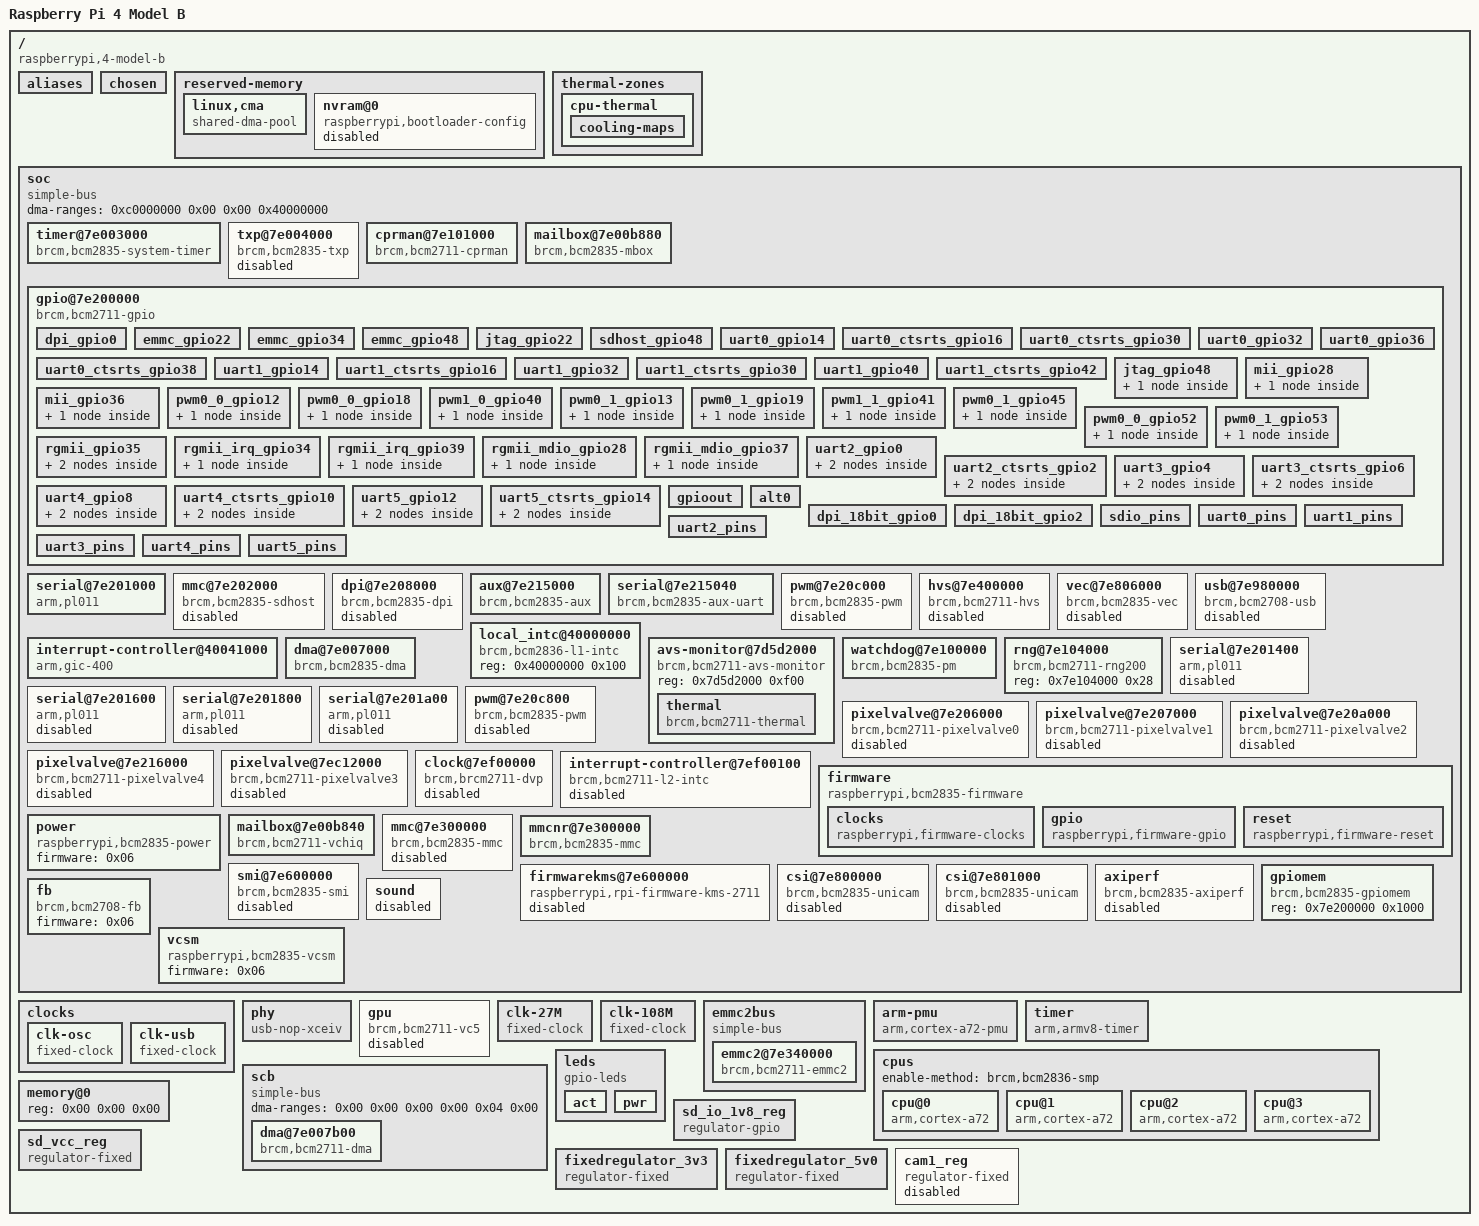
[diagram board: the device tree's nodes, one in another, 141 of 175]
/dts-v1/;

/memreserve/	0x0000000000000000 0x0000000000001000;
/ {
	compatible = "raspberrypi,4-model-b\0brcm,bcm2711";
	model = "Raspberry Pi 4 Model B";
	#address-cells = <0x02>;
	#size-cells = <0x01>;
	interrupt-parent = <0x01>;

	aliases {
		serial0 = "/soc/serial@7e215040";
		serial1 = "/soc/serial@7e201000";
		emmc2bus = "/emmc2bus";
		pcie0 = "/scb/pcie@7d500000";
		blconfig = "/reserved-memory/nvram@0";
		aux = "/soc/aux@7e215000";
		sound = "/soc/sound";
		soc = "/soc";
		dma = "/soc/dma@7e007000";
		watchdog = "/soc/watchdog@7e100000";
		random = "/soc/rng@7e104000";
		mailbox = "/soc/mailbox@7e00b880";
		gpio = "/soc/gpio@7e200000";
		uart0 = "/soc/serial@7e201000";
		uart1 = "/soc/serial@7e215040";
		sdhost = "/soc/mmc@7e202000";
		mmc = "/soc/mmc@7e300000";
		mmc1 = "/soc/mmcnr@7e300000";
		mmc0 = "/emmc2bus/emmc2@7e340000";
		usb = "/soc/usb@7e980000";
		leds = "/leds";
		fb = "/soc/fb";
		thermal = "/soc/avs-monitor@7d5d2000/thermal";
		axiperf = "/soc/axiperf";
		mmc2 = "/soc/mmc@7e202000";
	};

	chosen {
		bootargs = "coherent_pool=1M 8250.nr_uarts=1 snd_bcm2835.enable_compat_alsa=0 snd_bcm2835.enable_hdmi=1";
	};

	reserved-memory {
		#address-cells = <0x02>;
		#size-cells = <0x01>;
		ranges;
		phandle = <0x41>;

		linux,cma {
			compatible = "shared-dma-pool";
			size = <0x4000000>;
			reusable;
			linux,cma-default;
			alloc-ranges = <0x00 0x00 0x30000000>;
			phandle = <0x42>;
		};

		nvram@0 {
			compatible = "raspberrypi,bootloader-config\0nvmem-rmem";
			#address-cells = <0x01>;
			#size-cells = <0x01>;
			reg = <0x00 0x00 0x00>;
			no-map;
			status = "disabled";
			phandle = <0x43>;
		};
	};

	thermal-zones {

		cpu-thermal {
			polling-delay-passive = <0x00>;
			polling-delay = <0x3e8>;
			coefficients = <0xfffffe19 0x641b8>;
			thermal-sensors = <0x02>;
			phandle = <0x44>;

			cooling-maps {
			};
		};
	};

	soc {
		compatible = "simple-bus";
		#address-cells = <0x01>;
		#size-cells = <0x01>;
		ranges = <0x7e000000 0x00 0xfe000000 0x1800000 0x7c000000 0x00 0xfc000000 0x2000000 0x40000000 0x00 0xff800000 0x800000>;
		dma-ranges = <0xc0000000 0x00 0x00 0x40000000>;
		phandle = <0x45>;

		timer@7e003000 {
			compatible = "brcm,bcm2835-system-timer";
			reg = <0x7e003000 0x1000>;
			interrupts = <0x00 0x40 0x04 0x00 0x41 0x04 0x00 0x42 0x04 0x00 0x43 0x04>;
			clock-frequency = <0xf4240>;
			phandle = <0x46>;
		};

		txp@7e004000 {
			compatible = "brcm,bcm2835-txp";
			reg = <0x7e004000 0x20>;
			interrupts = <0x00 0x4b 0x04>;
			status = "disabled";
			phandle = <0x47>;
		};

		cprman@7e101000 {
			compatible = "brcm,bcm2711-cprman";
			#clock-cells = <0x01>;
			reg = <0x7e101000 0x2000>;
			clocks = <0x03 0x04 0x00 0x04 0x01 0x04 0x02 0x05 0x00 0x05 0x01 0x05 0x02>;
			firmware = <0x06>;
			phandle = <0x07>;
		};

		mailbox@7e00b880 {
			compatible = "brcm,bcm2835-mbox";
			reg = <0x7e00b880 0x40>;
			interrupts = <0x00 0x21 0x04>;
			#mbox-cells = <0x00>;
			phandle = <0x22>;
		};

		gpio@7e200000 {
			compatible = "brcm,bcm2711-gpio";
			reg = <0x7e200000 0xb4>;
			interrupts = <0x00 0x71 0x04 0x00 0x72 0x04>;
			gpio-controller;
			#gpio-cells = <0x02>;
			interrupt-controller;
			#interrupt-cells = <0x02>;
			pinctrl-names = "default";
			gpio-line-names = "ID_SDA\0ID_SCL\0SDA1\0SCL1\0GPIO_GCLK\0GPIO5\0GPIO6\0SPI_CE1_N\0SPI_CE0_N\0SPI_MISO\0SPI_MOSI\0SPI_SCLK\0GPIO12\0GPIO13\0TXD1\0RXD1\0GPIO16\0GPIO17\0GPIO18\0GPIO19\0GPIO20\0GPIO21\0GPIO22\0GPIO23\0GPIO24\0GPIO25\0GPIO26\0GPIO27\0RGMII_MDIO\0RGMIO_MDC\0CTS0\0RTS0\0TXD0\0RXD0\0SD1_CLK\0SD1_CMD\0SD1_DATA0\0SD1_DATA1\0SD1_DATA2\0SD1_DATA3\0PWM0_MISO\0PWM1_MOSI\0STATUS_LED_G_CLK\0SPIFLASH_CE_N\0SDA0\0SCL0\0RGMII_RXCLK\0RGMII_RXCTL\0RGMII_RXD0\0RGMII_RXD1\0RGMII_RXD2\0RGMII_RXD3\0RGMII_TXCLK\0RGMII_TXCTL\0RGMII_TXD0\0RGMII_TXD1\0RGMII_TXD2\0RGMII_TXD3";
			phandle = <0x0f>;

			dpi_gpio0 {
				brcm,pins = <0x00 0x01 0x02 0x03 0x04 0x05 0x06 0x07 0x08 0x09 0x0a 0x0b 0x0c 0x0d 0x0e 0x0f 0x10 0x11 0x12 0x13 0x14 0x15 0x16 0x17 0x18 0x19 0x1a 0x1b>;
				brcm,function = <0x06>;
				phandle = <0x48>;
			};

			emmc_gpio22 {
				brcm,pins = <0x16 0x17 0x18 0x19 0x1a 0x1b>;
				brcm,function = <0x07>;
				phandle = <0x49>;
			};

			emmc_gpio34 {
				brcm,pins = <0x22 0x23 0x24 0x25 0x26 0x27>;
				brcm,function = <0x07>;
				brcm,pull = <0x00 0x02 0x02 0x02 0x02 0x02>;
				phandle = <0x4a>;
			};

			emmc_gpio48 {
				brcm,pins = <0x30 0x31 0x32 0x33 0x34 0x35>;
				brcm,function = <0x07>;
				phandle = <0x24>;
			};

			jtag_gpio22 {
				brcm,pins = <0x16 0x17 0x18 0x19 0x1a 0x1b>;
				brcm,function = <0x03>;
				phandle = <0x54>;
			};

			sdhost_gpio48 {
				brcm,pins = <0x30 0x31 0x32 0x33 0x34 0x35>;
				brcm,function = <0x04>;
				phandle = <0x57>;
			};

			uart0_gpio14 {
				brcm,pins = <0x0e 0x0f>;
				brcm,function = <0x04>;
				phandle = <0x5c>;
			};

			uart0_ctsrts_gpio16 {
				brcm,pins = <0x10 0x11>;
				brcm,function = <0x07>;
				phandle = <0x5d>;
			};

			uart0_ctsrts_gpio30 {
				brcm,pins = <0x1e 0x1f>;
				brcm,function = <0x07>;
				brcm,pull = <0x02 0x00>;
				phandle = <0x5e>;
			};

			uart0_gpio32 {
				brcm,pins = <0x20 0x21>;
				brcm,function = <0x07>;
				brcm,pull = <0x00 0x02>;
				phandle = <0x5f>;
			};

			uart0_gpio36 {
				brcm,pins = <0x24 0x25>;
				brcm,function = <0x06>;
				phandle = <0x60>;
			};

			uart0_ctsrts_gpio38 {
				brcm,pins = <0x26 0x27>;
				brcm,function = <0x06>;
				phandle = <0x61>;
			};

			uart1_gpio14 {
				brcm,pins = <0x0e 0x0f>;
				brcm,function = <0x02>;
				phandle = <0x62>;
			};

			uart1_ctsrts_gpio16 {
				brcm,pins = <0x10 0x11>;
				brcm,function = <0x02>;
				phandle = <0x63>;
			};

			uart1_gpio32 {
				brcm,pins = <0x20 0x21>;
				brcm,function = <0x02>;
				phandle = <0x64>;
			};

			uart1_ctsrts_gpio30 {
				brcm,pins = <0x1e 0x1f>;
				brcm,function = <0x02>;
				phandle = <0x65>;
			};

			uart1_gpio40 {
				brcm,pins = <0x28 0x29>;
				brcm,function = <0x02>;
				phandle = <0x66>;
			};

			uart1_ctsrts_gpio42 {
				brcm,pins = <0x2a 0x2b>;
				brcm,function = <0x02>;
				phandle = <0x67>;
			};

			jtag_gpio48 {
				phandle = <0x76>;

				pins-jtag {
					pins = "gpio48\0gpio49\0gpio50\0gpio51\0gpio52\0gpio53";
					function = "alt4";
				};
			};

			mii_gpio28 {
				phandle = <0x77>;

				pins-mii {
					pins = "gpio28\0gpio29\0gpio30\0gpio31";
					function = "alt4";
				};
			};

			mii_gpio36 {
				phandle = <0x78>;

				pins-mii {
					pins = "gpio36\0gpio37\0gpio38\0gpio39";
					function = "alt5";
				};
			};

			pwm0_0_gpio12 {
				phandle = <0x7a>;

				pin-pwm {
					pins = "gpio12";
					function = "alt0";
					bias-disable;
				};
			};

			pwm0_0_gpio18 {
				phandle = <0x7b>;

				pin-pwm {
					pins = "gpio18";
					function = "alt5";
					bias-disable;
				};
			};

			pwm1_0_gpio40 {
				phandle = <0x1a>;

				pin-pwm {
					pins = "gpio40";
					function = "alt0";
					bias-disable;
				};
			};

			pwm0_1_gpio13 {
				phandle = <0x7c>;

				pin-pwm {
					pins = "gpio13";
					function = "alt0";
					bias-disable;
				};
			};

			pwm0_1_gpio19 {
				phandle = <0x7d>;

				pin-pwm {
					pins = "gpio19";
					function = "alt5";
					bias-disable;
				};
			};

			pwm1_1_gpio41 {
				phandle = <0x1b>;

				pin-pwm {
					pins = "gpio41";
					function = "alt0";
					bias-disable;
				};
			};

			pwm0_1_gpio45 {
				phandle = <0x7e>;

				pin-pwm {
					pins = "gpio45";
					function = "alt0";
					bias-disable;
				};
			};

			pwm0_0_gpio52 {
				phandle = <0x7f>;

				pin-pwm {
					pins = "gpio52";
					function = "alt1";
					bias-disable;
				};
			};

			pwm0_1_gpio53 {
				phandle = <0x80>;

				pin-pwm {
					pins = "gpio53";
					function = "alt1";
					bias-disable;
				};
			};

			rgmii_gpio35 {
				phandle = <0x81>;

				pin-start-stop {
					pins = "gpio35";
					function = "alt4";
				};

				pin-rx-ok {
					pins = "gpio36";
					function = "alt4";
				};
			};

			rgmii_irq_gpio34 {
				phandle = <0x82>;

				pin-irq {
					pins = "gpio34";
					function = "alt5";
				};
			};

			rgmii_irq_gpio39 {
				phandle = <0x83>;

				pin-irq {
					pins = "gpio39";
					function = "alt4";
				};
			};

			rgmii_mdio_gpio28 {
				phandle = <0x84>;

				pins-mdio {
					pins = "gpio28\0gpio29";
					function = "alt5";
				};
			};

			rgmii_mdio_gpio37 {
				phandle = <0x85>;

				pins-mdio {
					pins = "gpio37\0gpio38";
					function = "alt4";
				};
			};

			uart2_gpio0 {
				phandle = <0x8c>;

				pin-tx {
					pins = "gpio0";
					function = "alt4";
					bias-disable;
				};

				pin-rx {
					pins = "gpio1";
					function = "alt4";
					bias-pull-up;
				};
			};

			uart2_ctsrts_gpio2 {
				phandle = <0x8d>;

				pin-cts {
					pins = "gpio2";
					function = "alt4";
					bias-pull-up;
				};

				pin-rts {
					pins = "gpio3";
					function = "alt4";
					bias-disable;
				};
			};

			uart3_gpio4 {
				phandle = <0x8e>;

				pin-tx {
					pins = "gpio4";
					function = "alt4";
					bias-disable;
				};

				pin-rx {
					pins = "gpio5";
					function = "alt4";
					bias-pull-up;
				};
			};

			uart3_ctsrts_gpio6 {
				phandle = <0x8f>;

				pin-cts {
					pins = "gpio6";
					function = "alt4";
					bias-pull-up;
				};

				pin-rts {
					pins = "gpio7";
					function = "alt4";
					bias-disable;
				};
			};

			uart4_gpio8 {
				phandle = <0x90>;

				pin-tx {
					pins = "gpio8";
					function = "alt4";
					bias-disable;
				};

				pin-rx {
					pins = "gpio9";
					function = "alt4";
					bias-pull-up;
				};
			};

			uart4_ctsrts_gpio10 {
				phandle = <0x91>;

				pin-cts {
					pins = "gpio10";
					function = "alt4";
					bias-pull-up;
				};

				pin-rts {
					pins = "gpio11";
					function = "alt4";
					bias-disable;
				};
			};

			uart5_gpio12 {
				phandle = <0x92>;

				pin-tx {
					pins = "gpio12";
					function = "alt4";
					bias-disable;
				};

				pin-rx {
					pins = "gpio13";
					function = "alt4";
					bias-pull-up;
				};
			};

			uart5_ctsrts_gpio14 {
				phandle = <0x93>;

				pin-cts {
					pins = "gpio14";
					function = "alt4";
					bias-pull-up;
				};

				pin-rts {
					pins = "gpio15";
					function = "alt4";
					bias-disable;
				};
			};

			gpioout {
				brcm,pins = <0x06>;
				brcm,function = <0x01>;
				phandle = <0x94>;
			};

			alt0 {
				brcm,pins = <0x04 0x05 0x07 0x08 0x09 0x0a 0x0b>;
				brcm,function = <0x04>;
				phandle = <0x95>;
			};

			dpi_18bit_gpio0 {
				brcm,pins = <0x00 0x01 0x02 0x03 0x04 0x05 0x06 0x07 0x08 0x09 0x0a 0x0b 0x0c 0x0d 0x0e 0x0f 0x10 0x11 0x12 0x13 0x14 0x15>;
				brcm,function = <0x06>;
				phandle = <0x96>;
			};

			dpi_18bit_gpio2 {
				brcm,pins = <0x02 0x03 0x04 0x05 0x06 0x07 0x08 0x09 0x0a 0x0b 0x0c 0x0d 0x0e 0x0f 0x10 0x11 0x12 0x13 0x14 0x15>;
				brcm,function = <0x06>;
				phandle = <0x97>;
			};

			sdio_pins {
				brcm,pins = <0x22 0x23 0x24 0x25 0x26 0x27>;
				brcm,function = <0x07>;
				brcm,pull = <0x00 0x02 0x02 0x02 0x02 0x02>;
				phandle = <0x25>;
			};

			uart0_pins {
				brcm,pins = <0x20 0x21>;
				brcm,function = <0x07>;
				brcm,pull = <0x00 0x02>;
				phandle = <0x08>;
			};

			uart1_pins {
				brcm,pins;
				brcm,function;
				brcm,pull;
				phandle = <0x15>;
			};

			uart2_pins {
				brcm,pins = <0x00 0x01>;
				brcm,function = <0x03>;
				brcm,pull = <0x00 0x02>;
				phandle = <0xa5>;
			};

			uart3_pins {
				brcm,pins = <0x04 0x05>;
				brcm,function = <0x03>;
				brcm,pull = <0x00 0x02>;
				phandle = <0xa6>;
			};

			uart4_pins {
				brcm,pins = <0x08 0x09>;
				brcm,function = <0x03>;
				brcm,pull = <0x00 0x02>;
				phandle = <0xa7>;
			};

			uart5_pins {
				brcm,pins = <0x0c 0x0d>;
				brcm,function = <0x03>;
				brcm,pull = <0x00 0x02>;
				phandle = <0xa8>;
			};
		};

		serial@7e201000 {
			compatible = "arm,pl011\0arm,primecell";
			reg = <0x7e201000 0x200>;
			interrupts = <0x00 0x79 0x04>;
			clocks = <0x07 0x13 0x07 0x14>;
			clock-names = "uartclk\0apb_pclk";
			arm,primecell-periphid = <0x241011>;
			pinctrl-names = "default";
			pinctrl-0 = <0x08 0x09>;
			uart-has-rtscts;
			status = "okay";
			cts-event-workaround;
			skip-init;
			phandle = <0x30>;
		};

		mmc@7e202000 {
			compatible = "brcm,bcm2835-sdhost";
			reg = <0x7e202000 0x100>;
			interrupts = <0x00 0x78 0x04>;
			clocks = <0x07 0x14>;
			status = "disabled";
			dmas = <0x0b 0x2000000d>;
			dma-names = "rx-tx";
			bus-width = <0x04>;
			brcm,overclock-50 = <0x00>;
			brcm,pio-limit = <0x01>;
			phandle = <0x39>;
		};

		dpi@7e208000 {
			compatible = "brcm,bcm2835-dpi";
			reg = <0x7e208000 0x8c>;
			clocks = <0x07 0x14 0x07 0x2c>;
			clock-names = "core\0pixel";
			#address-cells = <0x01>;
			#size-cells = <0x00>;
			status = "disabled";
			phandle = <0xad>;
		};

		aux@7e215000 {
			compatible = "brcm,bcm2835-aux";
			#clock-cells = <0x01>;
			reg = <0x7e215000 0x08>;
			clocks = <0x07 0x14>;
			phandle = <0x14>;
		};

		serial@7e215040 {
			compatible = "brcm,bcm2835-aux-uart";
			reg = <0x7e215040 0x40>;
			interrupts = <0x00 0x5d 0x04>;
			clocks = <0x14 0x00>;
			status = "okay";
			pinctrl-names = "default";
			pinctrl-0 = <0x15>;
			skip-init;
			phandle = <0x31>;
		};

		pwm@7e20c000 {
			compatible = "brcm,bcm2835-pwm";
			reg = <0x7e20c000 0x28>;
			clocks = <0x07 0x1e>;
			assigned-clocks = <0x07 0x1e>;
			assigned-clock-rates = <0x989680>;
			#pwm-cells = <0x02>;
			status = "disabled";
			phandle = <0xb1>;
		};

		hvs@7e400000 {
			compatible = "brcm,bcm2711-hvs";
			reg = <0x7e400000 0x6000>;
			interrupts = <0x00 0x61 0x04>;
			clocks = <0x16 0x04>;
			status = "disabled";
			phandle = <0xb2>;
		};

		vec@7e806000 {
			compatible = "brcm,bcm2835-vec";
			reg = <0x7e806000 0x1000>;
			clocks = <0x07 0x18>;
			interrupts = <0x00 0x7b 0x04>;
			status = "disabled";
			power-domains = <0x13 0x07>;
			phandle = <0xb3>;
		};

		usb@7e980000 {
			compatible = "brcm,bcm2708-usb";
			reg = <0x7e980000 0x10000 0x7e00b200 0x200>;
			interrupts = <0x00 0x49 0x04 0x00 0x28 0x04>;
			#address-cells = <0x01>;
			#size-cells = <0x00>;
			clocks = <0x18>;
			clock-names = "otg";
			phys = <0x19>;
			phy-names = "usb2-phy";
			power-domains = <0x13 0x06>;
			interrupt-names = "usb\0soft";
			status = "disabled";
			phandle = <0xb4>;
		};

		local_intc@40000000 {
			compatible = "brcm,bcm2836-l1-intc";
			reg = <0x40000000 0x100>;
			phandle = <0xb5>;
		};

		interrupt-controller@40041000 {
			interrupt-controller;
			#interrupt-cells = <0x03>;
			compatible = "arm,gic-400";
			reg = <0x40041000 0x1000 0x40042000 0x2000 0x40044000 0x2000 0x40046000 0x2000>;
			interrupts = <0x01 0x09 0xf04>;
			phandle = <0x01>;
		};

		avs-monitor@7d5d2000 {
			compatible = "brcm,bcm2711-avs-monitor\0syscon\0simple-mfd";
			reg = <0x7d5d2000 0xf00>;
			phandle = <0xb6>;

			thermal {
				compatible = "brcm,bcm2711-thermal";
				#thermal-sensor-cells = <0x00>;
				phandle = <0x02>;
			};
		};

		dma@7e007000 {
			compatible = "brcm,bcm2835-dma";
			reg = <0x7e007000 0xb00>;
			interrupts = <0x00 0x50 0x04 0x00 0x51 0x04 0x00 0x52 0x04 0x00 0x53 0x04 0x00 0x54 0x04 0x00 0x55 0x04 0x00 0x56 0x04 0x00 0x57 0x04 0x00 0x57 0x04 0x00 0x58 0x04 0x00 0x58 0x04>;
			interrupt-names = "dma0\0dma1\0dma2\0dma3\0dma4\0dma5\0dma6\0dma7\0dma8\0dma9\0dma10";
			#dma-cells = <0x01>;
			brcm,dma-channel-mask = <0x7f5>;
			phandle = <0x0b>;
		};

		watchdog@7e100000 {
			compatible = "brcm,bcm2835-pm\0brcm,bcm2835-pm-wdt";
			#power-domain-cells = <0x01>;
			#reset-cells = <0x01>;
			reg = <0x7e100000 0x114 0x7e00a000 0x24 0x7ec11000 0x20>;
			clocks = <0x07 0x15 0x07 0x1d 0x07 0x17 0x07 0x16>;
			clock-names = "v3d\0peri_image\0h264\0isp";
			system-power-controller;
			phandle = <0x37>;
		};

		rng@7e104000 {
			compatible = "brcm,bcm2711-rng200";
			reg = <0x7e104000 0x28>;
			status = "okay";
			phandle = <0x38>;
		};

		serial@7e201400 {
			compatible = "arm,pl011\0arm,primecell";
			reg = <0x7e201400 0x200>;
			interrupts = <0x00 0x79 0x04>;
			clocks = <0x07 0x13 0x07 0x14>;
			clock-names = "uartclk\0apb_pclk";
			arm,primecell-periphid = <0x241011>;
			status = "disabled";
			phandle = <0xb7>;
		};

		serial@7e201600 {
			compatible = "arm,pl011\0arm,primecell";
			reg = <0x7e201600 0x200>;
			interrupts = <0x00 0x79 0x04>;
			clocks = <0x07 0x13 0x07 0x14>;
			clock-names = "uartclk\0apb_pclk";
			arm,primecell-periphid = <0x241011>;
			status = "disabled";
			phandle = <0xb8>;
		};

		serial@7e201800 {
			compatible = "arm,pl011\0arm,primecell";
			reg = <0x7e201800 0x200>;
			interrupts = <0x00 0x79 0x04>;
			clocks = <0x07 0x13 0x07 0x14>;
			clock-names = "uartclk\0apb_pclk";
			arm,primecell-periphid = <0x241011>;
			status = "disabled";
			phandle = <0xb9>;
		};

		serial@7e201a00 {
			compatible = "arm,pl011\0arm,primecell";
			reg = <0x7e201a00 0x200>;
			interrupts = <0x00 0x79 0x04>;
			clocks = <0x07 0x13 0x07 0x14>;
			clock-names = "uartclk\0apb_pclk";
			arm,primecell-periphid = <0x241011>;
			status = "disabled";
			phandle = <0xba>;
		};

		pixelvalve@7e206000 {
			compatible = "brcm,bcm2711-pixelvalve0";
			reg = <0x7e206000 0x100>;
			interrupts = <0x00 0x6d 0x04>;
			status = "disabled";
			phandle = <0xc3>;
		};

		pixelvalve@7e207000 {
			compatible = "brcm,bcm2711-pixelvalve1";
			reg = <0x7e207000 0x100>;
			interrupts = <0x00 0x6e 0x04>;
			status = "disabled";
			phandle = <0xc4>;
		};

		pixelvalve@7e20a000 {
			compatible = "brcm,bcm2711-pixelvalve2";
			reg = <0x7e20a000 0x100>;
			interrupts = <0x00 0x65 0x04>;
			status = "disabled";
			phandle = <0xc5>;
		};

		pwm@7e20c800 {
			compatible = "brcm,bcm2835-pwm";
			reg = <0x7e20c800 0x28>;
			clocks = <0x07 0x1e>;
			assigned-clocks = <0x07 0x1e>;
			assigned-clock-rates = <0x989680>;
			#pwm-cells = <0x02>;
			status = "disabled";
			pinctrl-names = "default";
			pinctrl-0 = <0x1a 0x1b>;
			phandle = <0xc6>;
		};

		pixelvalve@7e216000 {
			compatible = "brcm,bcm2711-pixelvalve4";
			reg = <0x7e216000 0x100>;
			interrupts = <0x00 0x6e 0x04>;
			status = "disabled";
			phandle = <0xc7>;
		};

		pixelvalve@7ec12000 {
			compatible = "brcm,bcm2711-pixelvalve3";
			reg = <0x7ec12000 0x100>;
			interrupts = <0x00 0x6a 0x04>;
			status = "disabled";
			phandle = <0xc8>;
		};

		clock@7ef00000 {
			compatible = "brcm,brcm2711-dvp";
			reg = <0x7ef00000 0x10>;
			clocks = <0x1c>;
			#clock-cells = <0x01>;
			#reset-cells = <0x01>;
			status = "disabled";
			phandle = <0x1d>;
		};

		interrupt-controller@7ef00100 {
			compatible = "brcm,bcm2711-l2-intc\0brcm,l2-intc";
			reg = <0x7ef00100 0x30>;
			interrupts = <0x00 0x60 0x04>;
			interrupt-controller;
			#interrupt-cells = <0x01>;
			status = "disabled";
			phandle = <0x1f>;
		};

		firmware {
			compatible = "raspberrypi,bcm2835-firmware\0simple-mfd";
			#address-cells = <0x01>;
			#size-cells = <0x01>;
			mboxes = <0x22>;
			dma-ranges;
			phandle = <0x06>;

			clocks {
				compatible = "raspberrypi,firmware-clocks";
				#clock-cells = <0x01>;
				phandle = <0x16>;
			};

			gpio {
				compatible = "raspberrypi,firmware-gpio";
				gpio-controller;
				#gpio-cells = <0x02>;
				gpio-line-names = "BT_ON\0WL_ON\0PWR_LED_OFF\0GLOBAL_RESET\0VDD_SD_IO_SEL\0CAM_GPIO\0SD_PWR_ON\0SD_OC_N";
				status = "okay";
				phandle = <0x0a>;
			};

			reset {
				compatible = "raspberrypi,firmware-reset";
				#reset-cells = <0x01>;
				phandle = <0x2d>;
			};
		};

		power {
			compatible = "raspberrypi,bcm2835-power";
			firmware = <0x06>;
			#power-domain-cells = <0x01>;
			phandle = <0x13>;
		};

		mailbox@7e00b840 {
			compatible = "brcm,bcm2711-vchiq";
			reg = <0x7e00b840 0x3c>;
			interrupts = <0x00 0x22 0x04>;
			phandle = <0xcb>;
		};

		mmc@7e300000 {
			compatible = "brcm,bcm2835-mmc\0brcm,bcm2835-sdhci";
			reg = <0x7e300000 0x100>;
			interrupts = <0x00 0x7e 0x04>;
			clocks = <0x07 0x1c>;
			dmas = <0x0b 0x0b>;
			dma-names = "rx-tx";
			brcm,overclock-50 = <0x00>;
			status = "disabled";
			pinctrl-names = "default";
			pinctrl-0 = <0x24>;
			bus-width = <0x04>;
			phandle = <0x3a>;
		};

		mmcnr@7e300000 {
			compatible = "brcm,bcm2835-mmc\0brcm,bcm2835-sdhci";
			reg = <0x7e300000 0x100>;
			interrupts = <0x00 0x7e 0x04>;
			clocks = <0x07 0x1c>;
			dmas = <0x0b 0x0b>;
			dma-names = "rx-tx";
			brcm,overclock-50 = <0x00>;
			non-removable;
			status = "okay";
			pinctrl-names = "default";
			pinctrl-0 = <0x25>;
			bus-width = <0x04>;
			phandle = <0x3b>;
		};

		firmwarekms@7e600000 {
			compatible = "raspberrypi,rpi-firmware-kms-2711";
			reg = <0x7e600000 0x100>;
			interrupts = <0x00 0x70 0x04>;
			brcm,firmware = <0x06>;
			status = "disabled";
			phandle = <0xcc>;
		};

		smi@7e600000 {
			compatible = "brcm,bcm2835-smi";
			reg = <0x7e600000 0x100>;
			interrupts = <0x00 0x70 0x04>;
			clocks = <0x07 0x2a>;
			assigned-clocks = <0x07 0x2a>;
			assigned-clock-rates = <0x7735940>;
			dmas = <0x0b 0x04>;
			dma-names = "rx-tx";
			status = "disabled";
			phandle = <0xcd>;
		};

		csi@7e800000 {
			compatible = "brcm,bcm2835-unicam";
			reg = <0x7e800000 0x800 0x7e802000 0x04>;
			interrupts = <0x00 0x66 0x04>;
			clocks = <0x07 0x2d 0x16 0x04>;
			clock-names = "lp\0vpu";
			power-domains = <0x13 0x0c>;
			#address-cells = <0x01>;
			#size-cells = <0x00>;
			#clock-cells = <0x01>;
			status = "disabled";
			phandle = <0xce>;
		};

		csi@7e801000 {
			compatible = "brcm,bcm2835-unicam";
			reg = <0x7e801000 0x800 0x7e802004 0x04>;
			interrupts = <0x00 0x67 0x04>;
			clocks = <0x07 0x2e 0x16 0x04>;
			clock-names = "lp\0vpu";
			power-domains = <0x13 0x0d>;
			#address-cells = <0x01>;
			#size-cells = <0x00>;
			#clock-cells = <0x01>;
			status = "disabled";
			brcm,num-data-lanes = <0x02>;
			phandle = <0xcf>;
		};

		axiperf {
			compatible = "brcm,bcm2835-axiperf";
			reg = <0x7e009800 0x100 0x7ee08000 0x100>;
			firmware = <0x06>;
			status = "disabled";
			phandle = <0x3c>;
		};

		gpiomem {
			compatible = "brcm,bcm2835-gpiomem";
			reg = <0x7e200000 0x1000>;
		};

		fb {
			compatible = "brcm,bcm2708-fb";
			firmware = <0x06>;
			status = "okay";
			phandle = <0xd0>;
		};

		vcsm {
			compatible = "raspberrypi,bcm2835-vcsm";
			firmware = <0x06>;
			status = "okay";
			phandle = <0xd1>;
		};

		sound {
			status = "disabled";
			phandle = <0xd2>;
		};
	};

	clocks {

		clk-osc {
			compatible = "fixed-clock";
			#clock-cells = <0x00>;
			clock-output-names = "osc";
			clock-frequency = <0x337f980>;
			phandle = <0x03>;
		};

		clk-usb {
			compatible = "fixed-clock";
			#clock-cells = <0x00>;
			clock-output-names = "otg";
			clock-frequency = <0x1c9c3800>;
			phandle = <0x18>;
		};
	};

	phy {
		compatible = "usb-nop-xceiv";
		#phy-cells = <0x00>;
		phandle = <0x19>;
	};

	gpu {
		compatible = "brcm,bcm2711-vc5";
		status = "disabled";
		phandle = <0xd3>;
	};

	clk-27M {
		#clock-cells = <0x00>;
		compatible = "fixed-clock";
		clock-frequency = <0x19bfcc0>;
		clock-output-names = "27MHz-clock";
		phandle = <0x1e>;
	};

	clk-108M {
		#clock-cells = <0x00>;
		compatible = "fixed-clock";
		clock-frequency = <0x66ff300>;
		clock-output-names = "108MHz-clock";
		phandle = <0x1c>;
	};

	emmc2bus {
		compatible = "simple-bus";
		#address-cells = <0x02>;
		#size-cells = <0x01>;
		ranges = <0x00 0x7e000000 0x00 0xfe000000 0x1800000>;
		dma-ranges = <0x00 0xc0000000 0x00 0x00 0x40000000>;
		phandle = <0xd4>;

		emmc2@7e340000 {
			compatible = "brcm,bcm2711-emmc2";
			reg = <0x00 0x7e340000 0x100>;
			interrupts = <0x00 0x7e 0x04>;
			clocks = <0x07 0x33>;
			status = "okay";
			vqmmc-supply = <0x26>;
			vmmc-supply = <0x27>;
			broken-cd;
			mmc-ddr-3_3v;
			phandle = <0x3f>;
		};
	};

	arm-pmu {
		compatible = "arm,cortex-a72-pmu\0arm,armv8-pmuv3";
		interrupts = <0x00 0x10 0x04 0x00 0x11 0x04 0x00 0x12 0x04 0x00 0x13 0x04>;
		interrupt-affinity = <0x28 0x29 0x2a 0x2b>;
	};

	timer {
		compatible = "arm,armv8-timer";
		interrupts = <0x01 0x0d 0xf08 0x01 0x0e 0xf08 0x01 0x0b 0xf08 0x01 0x0a 0xf08>;
		arm,cpu-registers-not-fw-configured;
	};

	cpus {
		#address-cells = <0x01>;
		#size-cells = <0x00>;
		enable-method = "brcm,bcm2836-smp";
		phandle = <0xd5>;

		cpu@0 {
			device_type = "cpu";
			compatible = "arm,cortex-a72";
			reg = <0x00>;
			enable-method = "spin-table";
			cpu-release-addr = <0x00 0xd8>;
			phandle = <0x28>;
		};

		cpu@1 {
			device_type = "cpu";
			compatible = "arm,cortex-a72";
			reg = <0x01>;
			enable-method = "spin-table";
			cpu-release-addr = <0x00 0xe0>;
			phandle = <0x29>;
		};

		cpu@2 {
			device_type = "cpu";
			compatible = "arm,cortex-a72";
			reg = <0x02>;
			enable-method = "spin-table";
			cpu-release-addr = <0x00 0xe8>;
			phandle = <0x2a>;
		};

		cpu@3 {
			device_type = "cpu";
			compatible = "arm,cortex-a72";
			reg = <0x03>;
			enable-method = "spin-table";
			cpu-release-addr = <0x00 0xf0>;
			phandle = <0x2b>;
		};
	};

	scb {
		compatible = "simple-bus";
		#address-cells = <0x02>;
		#size-cells = <0x02>;
		ranges = <0x00 0x7c000000 0x00 0xfc000000 0x00 0x3800000 0x00 0x40000000 0x00 0xff800000 0x00 0x800000 0x06 0x00 0x06 0x00 0x00 0x40000000 0x00 0x00 0x00 0x00 0x00 0xfc000000>;
		dma-ranges = <0x00 0x00 0x00 0x00 0x04 0x00>;
		phandle = <0xd6>;

		dma@7e007b00 {
			compatible = "brcm,bcm2711-dma";
			reg = <0x00 0x7e007b00 0x00 0x400>;
			interrupts = <0x00 0x59 0x04 0x00 0x5a 0x04 0x00 0x5b 0x04 0x00 0x5c 0x04>;
			interrupt-names = "dma11\0dma12\0dma13\0dma14";
			#dma-cells = <0x01>;
			brcm,dma-channel-mask = <0x7000>;
			phandle = <0x40>;
		};
	};

	leds {
		compatible = "gpio-leds";
		phandle = <0xda>;

		act {
			label = "led0";
			default-state = "keep";
			linux,default-trigger = "mmc0";
			gpios = <0x0f 0x2a 0x00>;
			phandle = <0x3d>;
		};

		pwr {
			label = "led1";
			gpios = <0x0a 0x02 0x01>;
			default-state = "keep";
			linux,default-trigger = "default-on";
			phandle = <0x3e>;
		};
	};

	memory@0 {
		device_type = "memory";
		reg = <0x00 0x00 0x00>;
	};

	sd_io_1v8_reg {
		compatible = "regulator-gpio";
		regulator-name = "vdd-sd-io";
		regulator-min-microvolt = <0x1b7740>;
		regulator-max-microvolt = <0x325aa0>;
		regulator-boot-on;
		regulator-always-on;
		regulator-settling-time-us = <0x1388>;
		gpios = <0x0a 0x04 0x00>;
		states = <0x1b7740 0x01 0x325aa0 0x00>;
		status = "okay";
		phandle = <0x26>;
	};

	sd_vcc_reg {
		compatible = "regulator-fixed";
		regulator-name = "vcc-sd";
		regulator-min-microvolt = <0x325aa0>;
		regulator-max-microvolt = <0x325aa0>;
		regulator-boot-on;
		enable-active-high;
		gpio = <0x0a 0x06 0x00>;
		phandle = <0x27>;
	};

	__overrides__ {
		cam0-pwdn-ctrl;
		cam0-pwdn;
		cam0-led-ctrl;
		cam0-led;
		cache_line_size;
		uart0 = "\0\0\0status";
		uart1 = [00 00 01 73 74 61 74 75 73 00];
		watchdog = "\0\0\astatus";
		random = "\0\0\08status";
		sd_overclock = "\0\0\09brcm,overclock-50:0";
		sd_force_pio = "\0\0\09brcm,force-pio?";
		sd_pio_limit = "\0\0\09brcm,pio-limit:0";
		sd_debug = "\0\0\09brcm,debug";
		sdio_overclock = "\0\0\0:brcm,overclock-50:0\0\0\0\0;brcm,overclock-50:0";
		axiperf = "\0\0\0<status";
		arm_freq;
		act_led_gpio = "\0\0\0=gpios:4";
		act_led_activelow = "\0\0\0=gpios:8";
		act_led_trigger = "\0\0\0=linux,default-trigger";
		pwr_led_gpio = "\0\0\0>gpios:4";
		pwr_led_activelow = "\0\0\0>gpios:8";
		pwr_led_trigger = "\0\0\0>linux,default-trigger";
		eth_led0 = "\0\0\0.led-modes:0";
		eth_led1 = "\0\0\0.led-modes:4";
		sd_poll_once = "\0\0\0?non-removable?";
		spi_dma4 = <0x33 0x646d6173 0x3a303d00 0x40 0x33 0x646d6173 0x3a383d00 0x40>;
	};

	fixedregulator_3v3 {
		compatible = "regulator-fixed";
		regulator-always-on;
		regulator-max-microvolt = <0x325aa0>;
		regulator-min-microvolt = <0x325aa0>;
		regulator-name = "3v3";
		phandle = <0xdb>;
	};

	fixedregulator_5v0 {
		compatible = "regulator-fixed";
		regulator-always-on;
		regulator-max-microvolt = <0x4c4b40>;
		regulator-min-microvolt = <0x4c4b40>;
		regulator-name = "5v0";
		phandle = <0xdc>;
	};

	cam1_reg {
		compatible = "regulator-fixed";
		regulator-name = "cam1-reg";
		enable-active-high;
		status = "disabled";
		gpio = <0x0a 0x05 0x00>;
		phandle = <0xdf>;
	};

	__symbols__ {
		rmem = "/reserved-memory";
		cma = "/reserved-memory/linux,cma";
		blconfig = "/reserved-memory/nvram@0";
		cpu_thermal = "/thermal-zones/cpu-thermal";
		soc = "/soc";
		system_timer = "/soc/timer@7e003000";
		txp = "/soc/txp@7e004000";
		clocks = "/soc/cprman@7e101000";
		mailbox = "/soc/mailbox@7e00b880";
		gpio = "/soc/gpio@7e200000";
		dpi_gpio0 = "/soc/gpio@7e200000/dpi_gpio0";
		emmc_gpio22 = "/soc/gpio@7e200000/emmc_gpio22";
		emmc_gpio34 = "/soc/gpio@7e200000/emmc_gpio34";
		emmc_gpio48 = "/soc/gpio@7e200000/emmc_gpio48";
		jtag_gpio22 = "/soc/gpio@7e200000/jtag_gpio22";
		sdhost_gpio48 = "/soc/gpio@7e200000/sdhost_gpio48";
		uart0_gpio14 = "/soc/gpio@7e200000/uart0_gpio14";
		uart0_ctsrts_gpio16 = "/soc/gpio@7e200000/uart0_ctsrts_gpio16";
		uart0_ctsrts_gpio30 = "/soc/gpio@7e200000/uart0_ctsrts_gpio30";
		uart0_gpio32 = "/soc/gpio@7e200000/uart0_gpio32";
		uart0_gpio36 = "/soc/gpio@7e200000/uart0_gpio36";
		uart0_ctsrts_gpio38 = "/soc/gpio@7e200000/uart0_ctsrts_gpio38";
		uart1_gpio14 = "/soc/gpio@7e200000/uart1_gpio14";
		uart1_ctsrts_gpio16 = "/soc/gpio@7e200000/uart1_ctsrts_gpio16";
		uart1_gpio32 = "/soc/gpio@7e200000/uart1_gpio32";
		uart1_ctsrts_gpio30 = "/soc/gpio@7e200000/uart1_ctsrts_gpio30";
		uart1_gpio40 = "/soc/gpio@7e200000/uart1_gpio40";
		uart1_ctsrts_gpio42 = "/soc/gpio@7e200000/uart1_ctsrts_gpio42";
		jtag_gpio48 = "/soc/gpio@7e200000/jtag_gpio48";
		mii_gpio28 = "/soc/gpio@7e200000/mii_gpio28";
		mii_gpio36 = "/soc/gpio@7e200000/mii_gpio36";
		pwm0_0_gpio12 = "/soc/gpio@7e200000/pwm0_0_gpio12";
		pwm0_0_gpio18 = "/soc/gpio@7e200000/pwm0_0_gpio18";
		pwm1_0_gpio40 = "/soc/gpio@7e200000/pwm1_0_gpio40";
		pwm0_1_gpio13 = "/soc/gpio@7e200000/pwm0_1_gpio13";
		pwm0_1_gpio19 = "/soc/gpio@7e200000/pwm0_1_gpio19";
		pwm1_1_gpio41 = "/soc/gpio@7e200000/pwm1_1_gpio41";
		pwm0_1_gpio45 = "/soc/gpio@7e200000/pwm0_1_gpio45";
		pwm0_0_gpio52 = "/soc/gpio@7e200000/pwm0_0_gpio52";
		pwm0_1_gpio53 = "/soc/gpio@7e200000/pwm0_1_gpio53";
		rgmii_gpio35 = "/soc/gpio@7e200000/rgmii_gpio35";
		rgmii_irq_gpio34 = "/soc/gpio@7e200000/rgmii_irq_gpio34";
		rgmii_irq_gpio39 = "/soc/gpio@7e200000/rgmii_irq_gpio39";
		rgmii_mdio_gpio28 = "/soc/gpio@7e200000/rgmii_mdio_gpio28";
		rgmii_mdio_gpio37 = "/soc/gpio@7e200000/rgmii_mdio_gpio37";
		uart2_ctsrts_gpio2 = "/soc/gpio@7e200000/uart2_ctsrts_gpio2";
		uart3_gpio4 = "/soc/gpio@7e200000/uart3_gpio4";
		uart3_ctsrts_gpio6 = "/soc/gpio@7e200000/uart3_ctsrts_gpio6";
		uart4_gpio8 = "/soc/gpio@7e200000/uart4_gpio8";
		uart4_ctsrts_gpio10 = "/soc/gpio@7e200000/uart4_ctsrts_gpio10";
		uart5_gpio12 = "/soc/gpio@7e200000/uart5_gpio12";
		uart5_ctsrts_gpio14 = "/soc/gpio@7e200000/uart5_ctsrts_gpio14";
		gpioout = "/soc/gpio@7e200000/gpioout";
		alt0 = "/soc/gpio@7e200000/alt0";
		dpi_18bit_gpio0 = "/soc/gpio@7e200000/dpi_18bit_gpio0";
		dpi_18bit_gpio2 = "/soc/gpio@7e200000/dpi_18bit_gpio2";
		sdio_pins = "/soc/gpio@7e200000/sdio_pins";
		uart0_pins = "/soc/gpio@7e200000/uart0_pins";
		uart1_pins = "/soc/gpio@7e200000/uart1_pins";
		uart2_pins = "/soc/gpio@7e200000/uart2_pins";
		uart3_pins = "/soc/gpio@7e200000/uart3_pins";
		uart4_pins = "/soc/gpio@7e200000/uart4_pins";
		uart5_pins = "/soc/gpio@7e200000/uart5_pins";
		uart0 = "/soc/serial@7e201000";
		sdhost = "/soc/mmc@7e202000";
		dpi = "/soc/dpi@7e208000";
		aux = "/soc/aux@7e215000";
		uart1 = "/soc/serial@7e215040";
		pwm = "/soc/pwm@7e20c000";
		hvs = "/soc/hvs@7e400000";
		vec = "/soc/vec@7e806000";
		usb = "/soc/usb@7e980000";
		local_intc = "/soc/local_intc@40000000";
		gicv2 = "/soc/interrupt-controller@40041000";
		avs_monitor = "/soc/avs-monitor@7d5d2000";
		thermal = "/soc/avs-monitor@7d5d2000/thermal";
		dma = "/soc/dma@7e007000";
		watchdog = "/soc/watchdog@7e100000";
		pm = "/soc/watchdog@7e100000";
		random = "/soc/rng@7e104000";
		uart2 = "/soc/serial@7e201400";
		uart3 = "/soc/serial@7e201600";
		uart4 = "/soc/serial@7e201800";
		uart5 = "/soc/serial@7e201a00";
		pixelvalve0 = "/soc/pixelvalve@7e206000";
		pixelvalve1 = "/soc/pixelvalve@7e207000";
		pixelvalve2 = "/soc/pixelvalve@7e20a000";
		pwm1 = "/soc/pwm@7e20c800";
		pixelvalve4 = "/soc/pixelvalve@7e216000";
		pixelvalve3 = "/soc/pixelvalve@7ec12000";
		dvp = "/soc/clock@7ef00000";
		aon_intr = "/soc/interrupt-controller@7ef00100";
		firmware = "/soc/firmware";
		firmware_clocks = "/soc/firmware/clocks";
		expgpio = "/soc/firmware/gpio";
		reset = "/soc/firmware/reset";
		power = "/soc/power";
		vchiq = "/soc/mailbox@7e00b840";
		sdhci = "/soc/mmc@7e300000";
		mmc = "/soc/mmc@7e300000";
		mmcnr = "/soc/mmcnr@7e300000";
		firmwarekms = "/soc/firmwarekms@7e600000";
		smi = "/soc/smi@7e600000";
		csi0 = "/soc/csi@7e800000";
		csi1 = "/soc/csi@7e801000";
		axiperf = "/soc/axiperf";
		fb = "/soc/fb";
		vcsm = "/soc/vcsm";
		sound = "/soc/sound";
		clk_osc = "/clocks/clk-osc";
		clk_usb = "/clocks/clk-usb";
		usbphy = "/phy";
		vc4 = "/gpu";
		clk_27MHz = "/clk-27M";
		clk_108MHz = "/clk-108M";
		emmc2bus = "/emmc2bus";
		emmc2 = "/emmc2bus/emmc2@7e340000";
		cpus = "/cpus";
		cpu0 = "/cpus/cpu@0";
		cpu1 = "/cpus/cpu@1";
		cpu2 = "/cpus/cpu@2";
		cpu3 = "/cpus/cpu@3";
		scb = "/scb";
		pcie0 = "/scb/pcie@7d500000";
		dma40 = "/scb/dma@7e007b00";
		xhci = "/scb/xhci@7e9c0000";
		leds = "/leds";
		act_led = "/leds/act";
		pwr_led = "/leds/pwr";
		sd_io_1v8_reg = "/sd_io_1v8_reg";
		sd_vcc_reg = "/sd_vcc_reg";
		vdd_3v3_reg = "/fixedregulator_3v3";
		vdd_5v0_reg = "/fixedregulator_5v0";
		cam1_reg = "/cam1_reg";
	};
};
